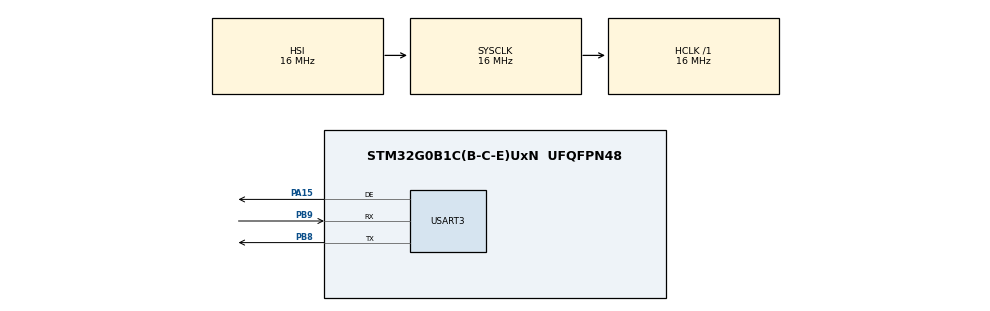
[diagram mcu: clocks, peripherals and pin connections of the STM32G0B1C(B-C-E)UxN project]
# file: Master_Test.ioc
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FREERTOS.Tasks01=defaultTask,0,128,StartDefaultTask,Default,NULL,Dynamic,NULL,NULL
Mcu.Family=STM32G0
Mcu.Name=STM32G0B1C(B-C-E)UxN
Mcu.Package=UFQFPN48
NVIC.USART3_4_5_6_LPUART1_IRQn=true\:3\:0\:false\:false\:true\:true\:true\:true\:true
PA15.Mode=Hardware Flow Control (RS485)
PA15.Signal=USART3_DE
PB8.Mode=Asynchronous
PB8.Signal=USART3_TX
PB9.Mode=Asynchronous
PB9.Signal=USART3_RX
ProjectManager.HeapSize=0x200
ProjectManager.StackSize=0x400
ProjectManager.TargetToolchain=STM32CubeIDE
RCC.AHBFreq_Value=16000000
RCC.CortexFreq_Value=16000000
RCC.EXTERNAL_CLOCK_VALUE=48000
RCC.HCLKFreq_Value=16000000
RCC.HSE_VALUE=8000000
RCC.HSI48_VALUE=48000000
RCC.HSI_VALUE=16000000
RCC.LSE_VALUE=32768
RCC.SYSCLKFreq_VALUE=16000000
RCC.USBFreq_Value=48000000
RCC.VCOOutputFreq_Value=128000000
USART3.VirtualMode-Asynchronous=VM_ASYNC
USART3.VirtualMode-Hardware\ Flow\ Control\ (RS485)=VM_ASYNC
VP_FREERTOS_VS_CMSIS_V1.Mode=CMSIS_V1
VP_SYS_VS_DBSignals.Mode=DisableDeadBatterySignals
board=custom

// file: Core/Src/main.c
/* USER CODE BEGIN Header */
/**
  ******************************************************************************
  * @file           : main.c
  * @brief          : Main program body
  ******************************************************************************
  * @attention
  *
  * Copyright (c) 2025 STMicroelectronics.
  * All rights reserved.
  *
  * This software is licensed under terms that can be found in the LICENSE file
  * in the root directory of this software component.
  * If no LICENSE file comes with this software, it is provided AS-IS.
  *
  ******************************************************************************
  */
/* USER CODE END Header */
#include "main.h"
#include "cmsis_os.h"
#include "usart.h"
#include "gpio.h"

void SystemClock_Config(void);
void MX_FREERTOS_Init(void);

int main(void)
{

  /* MCU Configuration--------------------------------------------------------*/

  /* Reset of all peripherals, Initializes the Flash interface and the Systick. */
  HAL_Init();

  /* Configure the system clock */
  SystemClock_Config();

  /* Initialize all configured peripherals */
  MX_GPIO_Init();
  MX_USART3_UART_Init();
	Modbus_task_Init();

  /* Call init function for freertos objects (in cmsis_os2.c) */
  MX_FREERTOS_Init();

  /* Start scheduler */
  osKernelStart();

  /* We should never get here as control is now taken by the scheduler */

  /* Infinite loop */
  while (1)
  {

  }
}

extern UART_HandleTypeDef huart3;
uint8_t d=50;
int yy ;
uint16_t aa=0x44;
unsigned short rr[10];
void StartDefaultTask(void const *argument) {
	  SetupModbusRTU(9600, 2);
	    SetTimeOut(200);
	/* Infinite loop */
	for (;;) {
		yy ++;
//		HAL_UART_Transmit_IT(&huart3, &d, 1);
//		HAL_UART_Transmit(&huart3, &d, 1,0xffff);
		HAL_Delay(200);
//		WriteModbusRegister(1,2,aa);
		ReadModbusRegister(1, 0, 10, rr);
//HAL_UART_Transmit(&huart3, &d, 1, 0xffff);
	}
	/* USER CODE END StartDefaultTask */
}

void SystemClock_Config(void)
{
  RCC_OscInitTypeDef RCC_OscInitStruct = {0};
  RCC_ClkInitTypeDef RCC_ClkInitStruct = {0};

  /** Configure the main internal regulator output voltage
  */
  HAL_PWREx_ControlVoltageScaling(PWR_REGULATOR_VOLTAGE_SCALE1);

  /** Initializes the RCC Oscillators according to the specified parameters
  * in the RCC_OscInitTypeDef structure.
  */
  RCC_OscInitStruct.OscillatorType = RCC_OSCILLATORTYPE_HSI;
  RCC_OscInitStruct.HSIState = RCC_HSI_ON;
  RCC_OscInitStruct.HSIDiv = RCC_HSI_DIV1;
  RCC_OscInitStruct.HSICalibrationValue = RCC_HSICALIBRATION_DEFAULT;
  RCC_OscInitStruct.PLL.PLLState = RCC_PLL_NONE;
  if (HAL_RCC_OscConfig(&RCC_OscInitStruct) != HAL_OK)
  {
    Error_Handler();
  }

  /** Initializes the CPU, AHB and APB buses clocks
  */
  RCC_ClkInitStruct.ClockType = RCC_CLOCKTYPE_HCLK|RCC_CLOCKTYPE_SYSCLK
                              |RCC_CLOCKTYPE_PCLK1;
  RCC_ClkInitStruct.SYSCLKSource = RCC_SYSCLKSOURCE_HSI;
  RCC_ClkInitStruct.AHBCLKDivider = RCC_SYSCLK_DIV1;
  RCC_ClkInitStruct.APB1CLKDivider = RCC_HCLK_DIV1;

  if (HAL_RCC_ClockConfig(&RCC_ClkInitStruct, FLASH_LATENCY_0) != HAL_OK)
  {
    Error_Handler();
  }
}

void Error_Handler(void)
{
  __disable_irq();
  while (1)
  {
  }
}

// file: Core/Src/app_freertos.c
/* USER CODE BEGIN Header */
/**
  ******************************************************************************
  * File Name          : app_freertos.c
  * Description        : Code for freertos applications
  ******************************************************************************
  * @attention
  *
  * Copyright (c) 2025 STMicroelectronics.
  * All rights reserved.
  *
  * This software is licensed under terms that can be found in the LICENSE file
  * in the root directory of this software component.
  * If no LICENSE file comes with this software, it is provided AS-IS.
  *
  ******************************************************************************
  */
/* USER CODE END Header */

#include "FreeRTOS.h"
#include "task.h"
#include "main.h"
#include "cmsis_os.h"

osThreadId defaultTaskHandle;

void StartDefaultTask(void const * argument);

void MX_FREERTOS_Init(void); /* (MISRA C 2004 rule 8.1) */

void MX_FREERTOS_Init(void) {

  /* Create the thread(s) */
  /* definition and creation of defaultTask */
  osThreadDef(defaultTask, StartDefaultTask, osPriorityNormal, 0, 128);
  defaultTaskHandle = osThreadCreate(osThread(defaultTask), NULL);

}

/* USER CODE BEGIN Header_StartDefaultTask */
///**
//  * @brief  Function implementing the defaultTask thread.
//  * @param  argument: Not used
//  * @retval None
//  */
/* USER CODE END Header_StartDefaultTask */
//void StartDefaultTask(void const * argument)
//{
  /* USER CODE BEGIN StartDefaultTask */
//  /* Infinite loop */
//  for(;;)
//  {
//    osDelay(1);
//  }
  /* USER CODE END StartDefaultTask */
//}
